# ZB204 register map
Vendor: GS; File version: 1.2
CPU: CM3 r2p0, little endian, MPU, no FPU, VTOR, 3 interrupt priority bits
Registers are 32-bit, read-write, reset 0x0 unless marked. A register's access mark holds for its fields unless they carry their own. Offsets are from the block's base; [hi:lo] are bit positions; {n}, {i} and the like mark numbered series.

## BPLC_SB_SNR — BPLC snr
Base 0x40503000
{0x0+4i} s_or_n[{i}] (i=0..979) — singnal or noise

## I2C — two-wire bidirectional serial bus
Base 0x400C0000
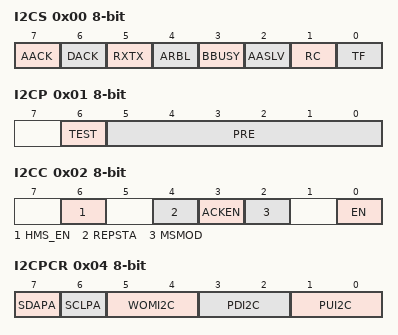
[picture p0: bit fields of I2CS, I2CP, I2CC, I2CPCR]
0x00 I2CS 8-bit — I2C Status Register
  [7] AACK — Address acknowledge error
    0=No error; 1=error
  [6] DACK — Data acknowledge received
    0=No acknowledge bit received; 1=Acknowledge bit received
  [5] RXTX — Receive or transmit
    0=Receive; 1=Transmit
  [4] ARBL — Arbitration lost
    0=not lost; 1=lost
  [3] BBUSY — I2C bus busy
    0=idle; 1=busy
  [2] AASLV — Addressed as a slave
    0=Not as a slave; 1=Addressed as a slave
  [1] RC — Receive Complete
    0=meaningless; 1=Indicates it is time to configure the receiver
  [0] TF — Transfer Complete Flag
    0=meaningless,; 1=Data or address transfer complete
0x01 I2CP 8-bit — I2C Clock Prescaler Register
  [6] TEST — Clock Test Enable
    0=Normal Mode; 1=Clock Test Mode Enable
  [5:0] PRE — Prescaler Divider Value
0x02 I2CC 8-bit — I2C Control Register
  [6] HMS_EN — High Speed Mode Enable
    0=Fast/Standard mode; 1=High-Speed Mode
  [4] REPSTA — Repeat Start
    0=No repeat start; 1=Generate repeat start
  [3] ACKEN — Acknowledge enable control
    0=disabled; 1=enabled
  [2] MSMOD — I2C master/slave mode selection contro
    0=Slave; 1=Master
  [0] EN — SLV_HSIE
    0=disabled; 1=enabled
0x03 I2CSA 8-bit — I2C Slave Address Register
0x04 I2CPCR 8-bit — I2C Port Control Register
  [7] SDAPA — SDA Port Assignment Bit
    0=primary function; 1=GPIO
  [6] SCLPA — SCL Port Assignment Bit
    0=primary function; 1=GPIO
  [5:4] WOMI2C — Addressed as a slave
  [3:2] PDI2C — Receive Complete
  [1:0] PUI2C — Transfer Complete Flag
0x05 I2CSHIR 8-bit — I2C slave high-speed indicator register
  [0] SLV_HS — Slave high speed mode
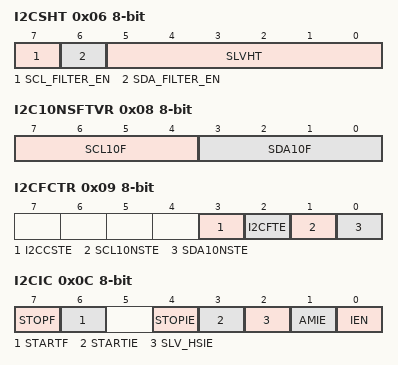
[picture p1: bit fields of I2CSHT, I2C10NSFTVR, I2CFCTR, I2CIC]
0x06 I2CSHT 8-bit — I2C slave SDA hold time Register
  [7] SCL_FILTER_EN — SCL Filter enable
    0=enable; 1=disable
  [6] SDA_FILTER_EN — SDA Filter enable
    0=enable; 1=disable
  [5:0] SLVHT — slave SDA line hold time configuration
0x07 I2CD 8-bit — I2C Data Register
0x08 I2C10NSFTVR 8-bit — I2C 10ns filter trimming value registe
  [7:4] SCL10F — I2C SCL line 10ns Filter Trimming value
  [3:0] SDA10F — I2C SDA line 10ns Filter Trimming value
0x09 I2CFCTR 8-bit — I2C filter and current source test register
  [3] I2CCSTE — I2C Current Source Test Enable Bit
    0=Disabled; 1=Enabled
  [2] I2CFTE — I2C Filter Test Enable Bit
    0=Disabled; 1=Enabled
  [1] SCL10NSTE — I2C SCL 10ns Filter Test Enable Bit
    0=50ns Filter; 1=10ns Filter
  [0] SDA10NSTE
    0=50ns Filter; 1=10ns Filter
0x0A I2CDDR 8-bit — I2C Port Direction Register
  [1:0] DDRI2C — I2C Data Direction Bits
0x0B I2CPDR 8-bit — I2C Port Data Register
  [1:0] PORTI2C — I2C Port Data Bits
0x0C I2CIC 8-bit — I2C Interrupt Control Register
  [7] STOPF — I2C stop Interrupt flag
    0=not detect; 1=detect
  [6] STARTF — I2C start Interrupt flag
    0=not detect; 1=detect
  [4] STOPIE — I2C stop Interrupt enable
    0=disabled; 1=enabled
  [3] STARTIE — I2C start Interrupt enable
    0=disabled; 1=enabled
  [2] SLV_HSIE — High-Speed Mode
    0=disabled; 1=enabled
  [1] AMIE — Address Match Interrupt Enable
    0=disabled; 1=enabled
  [0] IEN — I2C interrupt enable control.
    0=disabled; 1=enabled
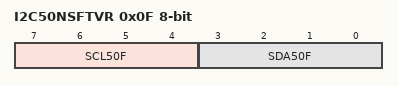
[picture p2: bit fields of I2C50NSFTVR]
0x0F I2C50NSFTVR 8-bit — I2C 50ns filter trimming value register
  [7:4] SCL50F — I2C SCL line 50ns Filter Trimming value
  [3:0] SDA50F — I2C SDA line 50ns Filter Trimming value

## PIT_CONTROL0 — Programmable Interrupt Timer Modules
Base 0x40070000
Same registers: PIT_CONTROL1 0x40080000
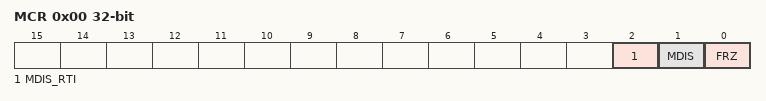
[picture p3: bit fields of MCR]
0x00 MCR — PIT Module Control Register
  [2] MDIS_RTI — Module Disable-RTI section
    0=enabled; 1=disabled
  [1] MDIS — Module Disable-PIT section
    0=Clock en; 1=Clock dis
  [0] FRZ — Freeze
    0=run in debug mode; 1=stopped in debug mode
